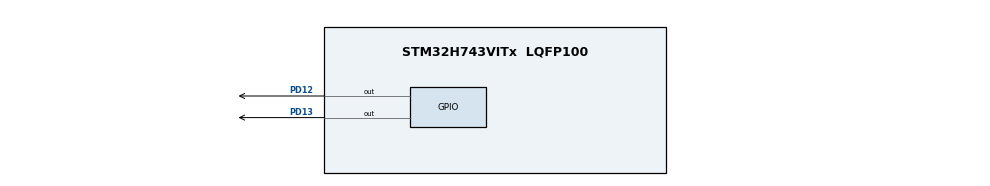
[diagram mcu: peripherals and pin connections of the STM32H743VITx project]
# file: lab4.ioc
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CORTEX_M7.default_mode_Activation=1
Mcu.Family=STM32H7
Mcu.Name=STM32H743VITx
Mcu.Package=LQFP100
NVIC.PriorityGroup=NVIC_PRIORITYGROUP_4
NVIC.TIM2_IRQn=true\:0\:0\:false\:false\:true\:true\:true\:true
NVIC.TIM3_IRQn=true\:0\:0\:false\:false\:true\:true\:true\:true
PA0.Signal=S_TIM2_CH1_ETR
PA6.Signal=S_TIM3_CH1
PD12.Signal=GPIO_Output
PD13.Signal=GPIO_Output
ProjectManager.HeapSize=0x200
ProjectManager.StackSize=0x400
ProjectManager.TargetToolchain=STM32CubeIDE
RCC.ADCFreq_Value=129000000
RCC.APB1Freq_Value=64000000
RCC.APB2Freq_Value=64000000
RCC.APB3Freq_Value=64000000
RCC.APB4Freq_Value=64000000
RCC.CortexFreq_Value=64000000
RCC.HCLKFreq_Value=64000000
RCC.SYSCLKFreq_VALUE=64000000
RCC.USBFreq_Value=129000000
SH.S_TIM2_CH1_ETR.0=TIM2_CH1
SH.S_TIM3_CH1.0=TIM3_CH1
TIM2.Period=1999
TIM2.Prescaler=6399
TIM3.Period=499
TIM3.Prescaler=6399
VP_MEMORYMAP_VS_MEMORYMAP.Mode=CurAppReg
VP_TIM2_VS_ClockSourceINT.Mode=Internal
VP_TIM3_VS_ClockSourceINT.Mode=Internal
board=custom

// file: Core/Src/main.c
/* USER CODE BEGIN Header */
/**
  ******************************************************************************
  * @file           : main.c
  * @brief          : Main program body
  ******************************************************************************
  * @attention
  *
  * Copyright (c) 2026 STMicroelectronics.
  * All rights reserved.
  *
  * This software is licensed under terms that can be found in the LICENSE file
  * in the root directory of this software component.
  * If no LICENSE file comes with this software, it is provided AS-IS.
  *
  ******************************************************************************
  */
/* USER CODE END Header */
#include "main.h"

TIM_HandleTypeDef htim2;
TIM_HandleTypeDef htim3;

void SystemClock_Config(void);
static void MPU_Config(void);
static void MX_GPIO_Init(void);
static void MX_TIM2_Init(void);
static void MX_TIM3_Init(void);

/* USER CODE BEGIN 0 */
uint8_t tim2_counter = 0; // Змінна для підрахунку кроків по 200 мс

void HAL_TIM_PeriodElapsedCallback(TIM_HandleTypeDef *htim)
{
    // Обробка TIM2 (Крок = 200 мс)
    if (htim->Instance == TIM2)
    {
        if (tim2_counter == 0)
        {
            // Перші 200 мс - вмикаємо світлодіод
            HAL_GPIO_WritePin(GPIOD, GPIO_PIN_12, GPIO_PIN_SET);
        }
        else
        {
            // Наступні 800 мс - вимикаємо
            HAL_GPIO_WritePin(GPIOD, GPIO_PIN_12, GPIO_PIN_RESET);
        }

        tim2_counter++;
        if (tim2_counter >= 5) // 5 кроків * 200 мс = 1000 мс (1 Гц)
        {
            tim2_counter = 0;  // Скидаємо лічильник для нового циклу
        }
    }
    // Обробка TIM3 (Крок = 50 мс)
    if (htim->Instance == TIM3)
    {
        // Оскільки потрібен імпульс 50 мс і пауза 50 мс (разом 100 мс = 10 Гц)
        HAL_GPIO_TogglePin(GPIOD, GPIO_PIN_13);
    }
}
/* USER CODE END 0 */

int main(void)
{

  /* MPU Configuration--------------------------------------------------------*/
  MPU_Config();

  /* MCU Configuration--------------------------------------------------------*/

  /* Reset of all peripherals, Initializes the Flash interface and the Systick. */
  HAL_Init();

  /* Configure the system clock */
  SystemClock_Config();

  /* Initialize all configured peripherals */
  MX_GPIO_Init();
  MX_TIM2_Init();
  MX_TIM3_Init();
  /* USER CODE BEGIN 2 */
  HAL_TIM_Base_Start_IT(&htim2); // Запуск TIM2 у режимі переривань
  HAL_TIM_Base_Start_IT(&htim3); // Запуск TIM3 у режимі переривань
  /* USER CODE END 2 */

  /* Infinite loop */
  while (1)
  {

  }
}

void SystemClock_Config(void)
{
  RCC_OscInitTypeDef RCC_OscInitStruct = {0};
  RCC_ClkInitTypeDef RCC_ClkInitStruct = {0};

  /** Supply configuration update enable
  */
  HAL_PWREx_ConfigSupply(PWR_LDO_SUPPLY);

  /** Configure the main internal regulator output voltage
  */
  __HAL_PWR_VOLTAGESCALING_CONFIG(PWR_REGULATOR_VOLTAGE_SCALE3);

  while(!__HAL_PWR_GET_FLAG(PWR_FLAG_VOSRDY)) {}

  /** Initializes the RCC Oscillators according to the specified parameters
  * in the RCC_OscInitTypeDef structure.
  */
  RCC_OscInitStruct.OscillatorType = RCC_OSCILLATORTYPE_HSI;
  RCC_OscInitStruct.HSIState = RCC_HSI_DIV1;
  RCC_OscInitStruct.HSICalibrationValue = RCC_HSICALIBRATION_DEFAULT;
  RCC_OscInitStruct.PLL.PLLState = RCC_PLL_NONE;
  if (HAL_RCC_OscConfig(&RCC_OscInitStruct) != HAL_OK)
  {
    Error_Handler();
  }

  /** Initializes the CPU, AHB and APB buses clocks
  */
  RCC_ClkInitStruct.ClockType = RCC_CLOCKTYPE_HCLK|RCC_CLOCKTYPE_SYSCLK
                              |RCC_CLOCKTYPE_PCLK1|RCC_CLOCKTYPE_PCLK2
                              |RCC_CLOCKTYPE_D3PCLK1|RCC_CLOCKTYPE_D1PCLK1;
  RCC_ClkInitStruct.SYSCLKSource = RCC_SYSCLKSOURCE_HSI;
  RCC_ClkInitStruct.SYSCLKDivider = RCC_SYSCLK_DIV1;
  RCC_ClkInitStruct.AHBCLKDivider = RCC_HCLK_DIV1;
  RCC_ClkInitStruct.APB3CLKDivider = RCC_APB3_DIV1;
  RCC_ClkInitStruct.APB1CLKDivider = RCC_APB1_DIV1;
  RCC_ClkInitStruct.APB2CLKDivider = RCC_APB2_DIV1;
  RCC_ClkInitStruct.APB4CLKDivider = RCC_APB4_DIV1;

  if (HAL_RCC_ClockConfig(&RCC_ClkInitStruct, FLASH_LATENCY_1) != HAL_OK)
  {
    Error_Handler();
  }
}

static void MX_TIM2_Init(void)
{

  TIM_ClockConfigTypeDef sClockSourceConfig = {0};
  TIM_MasterConfigTypeDef sMasterConfig = {0};

  htim2.Instance = TIM2;
  htim2.Init.Prescaler = 6399;
  htim2.Init.CounterMode = TIM_COUNTERMODE_UP;
  htim2.Init.Period = 1999;
  htim2.Init.ClockDivision = TIM_CLOCKDIVISION_DIV1;
  htim2.Init.AutoReloadPreload = TIM_AUTORELOAD_PRELOAD_DISABLE;
  if (HAL_TIM_Base_Init(&htim2) != HAL_OK)
  {
    Error_Handler();
  }
  sClockSourceConfig.ClockSource = TIM_CLOCKSOURCE_INTERNAL;
  if (HAL_TIM_ConfigClockSource(&htim2, &sClockSourceConfig) != HAL_OK)
  {
    Error_Handler();
  }
  sMasterConfig.MasterOutputTrigger = TIM_TRGO_RESET;
  sMasterConfig.MasterSlaveMode = TIM_MASTERSLAVEMODE_DISABLE;
  if (HAL_TIMEx_MasterConfigSynchronization(&htim2, &sMasterConfig) != HAL_OK)
  {
    Error_Handler();
  }

}

static void MX_TIM3_Init(void)
{

  TIM_ClockConfigTypeDef sClockSourceConfig = {0};
  TIM_MasterConfigTypeDef sMasterConfig = {0};

  htim3.Instance = TIM3;
  htim3.Init.Prescaler = 6399;
  htim3.Init.CounterMode = TIM_COUNTERMODE_UP;
  htim3.Init.Period = 499;
  htim3.Init.ClockDivision = TIM_CLOCKDIVISION_DIV1;
  htim3.Init.AutoReloadPreload = TIM_AUTORELOAD_PRELOAD_DISABLE;
  if (HAL_TIM_Base_Init(&htim3) != HAL_OK)
  {
    Error_Handler();
  }
  sClockSourceConfig.ClockSource = TIM_CLOCKSOURCE_INTERNAL;
  if (HAL_TIM_ConfigClockSource(&htim3, &sClockSourceConfig) != HAL_OK)
  {
    Error_Handler();
  }
  sMasterConfig.MasterOutputTrigger = TIM_TRGO_RESET;
  sMasterConfig.MasterSlaveMode = TIM_MASTERSLAVEMODE_DISABLE;
  if (HAL_TIMEx_MasterConfigSynchronization(&htim3, &sMasterConfig) != HAL_OK)
  {
    Error_Handler();
  }

}

static void MX_GPIO_Init(void)
{
  GPIO_InitTypeDef GPIO_InitStruct = {0};

  /* GPIO Ports Clock Enable */
  __HAL_RCC_GPIOA_CLK_ENABLE();
  __HAL_RCC_GPIOD_CLK_ENABLE();

  /*Configure GPIO pin Output Level */
  HAL_GPIO_WritePin(GPIOD, GPIO_PIN_12|GPIO_PIN_13, GPIO_PIN_RESET);

  /*Configure GPIO pins : PD12 PD13 */
  GPIO_InitStruct.Pin = GPIO_PIN_12|GPIO_PIN_13;
  GPIO_InitStruct.Mode = GPIO_MODE_OUTPUT_PP;
  GPIO_InitStruct.Pull = GPIO_NOPULL;
  GPIO_InitStruct.Speed = GPIO_SPEED_FREQ_LOW;
  HAL_GPIO_Init(GPIOD, &GPIO_InitStruct);

}

 /* MPU Configuration */

void MPU_Config(void)
{
  MPU_Region_InitTypeDef MPU_InitStruct = {0};

  /* Disables the MPU */
  HAL_MPU_Disable();

  /** Initializes and configures the Region and the memory to be protected
  */
  MPU_InitStruct.Enable = MPU_REGION_ENABLE;
  MPU_InitStruct.Number = MPU_REGION_NUMBER0;
  MPU_InitStruct.BaseAddress = 0x0;
  MPU_InitStruct.Size = MPU_REGION_SIZE_4GB;
  MPU_InitStruct.SubRegionDisable = 0x87;
  MPU_InitStruct.TypeExtField = MPU_TEX_LEVEL0;
  MPU_InitStruct.AccessPermission = MPU_REGION_NO_ACCESS;
  MPU_InitStruct.DisableExec = MPU_INSTRUCTION_ACCESS_DISABLE;
  MPU_InitStruct.IsShareable = MPU_ACCESS_SHAREABLE;
  MPU_InitStruct.IsCacheable = MPU_ACCESS_NOT_CACHEABLE;
  MPU_InitStruct.IsBufferable = MPU_ACCESS_NOT_BUFFERABLE;

  HAL_MPU_ConfigRegion(&MPU_InitStruct);
  /* Enables the MPU */
  HAL_MPU_Enable(MPU_PRIVILEGED_DEFAULT);

}

void Error_Handler(void)
{
  __disable_irq();
  while (1)
  {
  }
}
